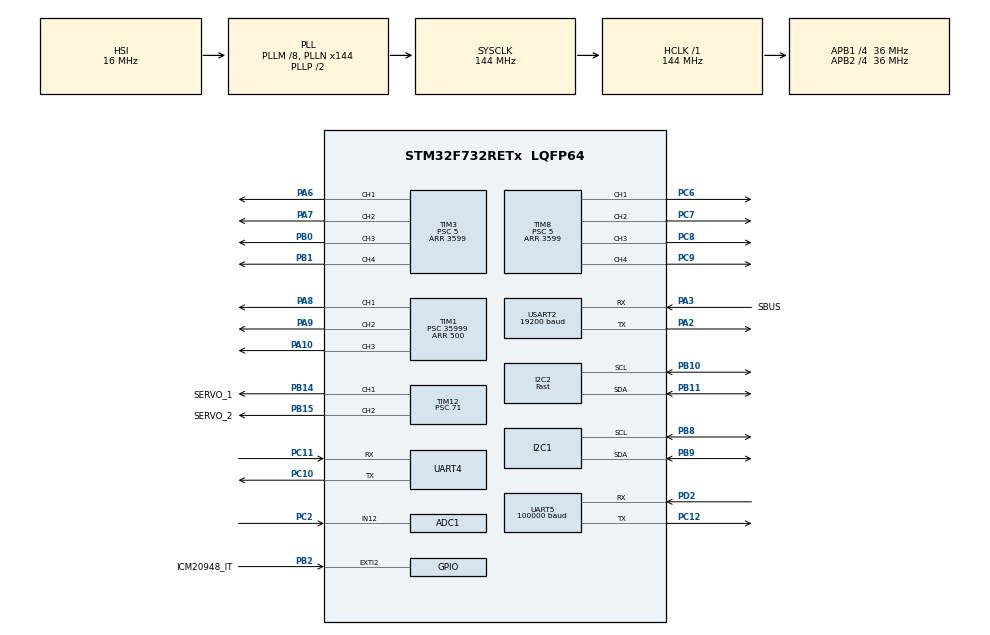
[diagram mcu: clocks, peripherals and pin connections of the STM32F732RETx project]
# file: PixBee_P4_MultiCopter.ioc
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ADC1.Channel-0\#ChannelRegularConversion=ADC_CHANNEL_12
ADC1.ContinuousConvMode=ENABLE
ADC1.DMAContinuousRequests=ENABLE
ADC1.NbrOfConversionFlag=1
ADC1.Rank-0\#ChannelRegularConversion=1
ADC1.Resolution=ADC_RESOLUTION_8B
ADC1.SamplingTime-0\#ChannelRegularConversion=ADC_SAMPLETIME_144CYCLES
ADC1.ScanConvMode=ADC_SCAN_ENABLE
ADC1.master=1
CORTEX_M7.ART_ACCELERATOR_ENABLE=1
CORTEX_M7.CPU_DCache=Enabled
CORTEX_M7.CPU_ICache=Enabled
CORTEX_M7.FlashInterface=AXI_Enabled
CORTEX_M7.MPU_Control=__NULL
CORTEX_M7.PREFETCH_ENABLE=1
CORTEX_M7.default_mode_Activation=1
Dma.ADC1.3.Direction=DMA_PERIPH_TO_MEMORY
Dma.ADC1.3.FIFOMode=DMA_FIFOMODE_DISABLE
Dma.ADC1.3.Instance=DMA2_Stream0
Dma.ADC1.3.MemDataAlignment=DMA_MDATAALIGN_HALFWORD
Dma.ADC1.3.MemInc=DMA_MINC_ENABLE
Dma.ADC1.3.Mode=DMA_CIRCULAR
Dma.ADC1.3.PeriphDataAlignment=DMA_PDATAALIGN_HALFWORD
Dma.ADC1.3.PeriphInc=DMA_PINC_DISABLE
Dma.ADC1.3.Priority=DMA_PRIORITY_LOW
Dma.Request0=UART5_RX
Dma.Request1=UART4_TX
Dma.Request2=USART2_TX
Dma.Request3=ADC1
Dma.UART4_TX.1.Direction=DMA_MEMORY_TO_PERIPH
Dma.UART4_TX.1.FIFOMode=DMA_FIFOMODE_DISABLE
Dma.UART4_TX.1.Instance=DMA1_Stream4
Dma.UART4_TX.1.MemDataAlignment=DMA_MDATAALIGN_BYTE
Dma.UART4_TX.1.MemInc=DMA_MINC_ENABLE
Dma.UART4_TX.1.Mode=DMA_NORMAL
Dma.UART4_TX.1.PeriphDataAlignment=DMA_PDATAALIGN_BYTE
Dma.UART4_TX.1.PeriphInc=DMA_PINC_DISABLE
Dma.UART4_TX.1.Priority=DMA_PRIORITY_LOW
Dma.UART5_RX.0.Direction=DMA_PERIPH_TO_MEMORY
Dma.UART5_RX.0.FIFOMode=DMA_FIFOMODE_DISABLE
Dma.UART5_RX.0.Instance=DMA1_Stream0
Dma.UART5_RX.0.MemDataAlignment=DMA_MDATAALIGN_BYTE
Dma.UART5_RX.0.MemInc=DMA_MINC_ENABLE
Dma.UART5_RX.0.Mode=DMA_NORMAL
Dma.UART5_RX.0.PeriphDataAlignment=DMA_PDATAALIGN_BYTE
Dma.UART5_RX.0.PeriphInc=DMA_PINC_DISABLE
Dma.UART5_RX.0.Priority=DMA_PRIORITY_LOW
Dma.USART2_TX.2.Direction=DMA_MEMORY_TO_PERIPH
Dma.USART2_TX.2.FIFOMode=DMA_FIFOMODE_DISABLE
Dma.USART2_TX.2.Instance=DMA1_Stream6
Dma.USART2_TX.2.MemDataAlignment=DMA_MDATAALIGN_BYTE
Dma.USART2_TX.2.MemInc=DMA_MINC_ENABLE
Dma.USART2_TX.2.Mode=DMA_NORMAL
Dma.USART2_TX.2.PeriphDataAlignment=DMA_PDATAALIGN_BYTE
Dma.USART2_TX.2.PeriphInc=DMA_PINC_DISABLE
Dma.USART2_TX.2.Priority=DMA_PRIORITY_LOW
I2C1.Timing=0x00808CD2
I2C2.I2C_Speed_Mode=I2C_Fast
I2C2.Timing=0x00301739
Mcu.Family=STM32F7
Mcu.Name=STM32F732RETx
Mcu.Package=LQFP64
NVIC.DMA1_Stream0_IRQn=true\:4\:0\:true\:false\:true\:false\:true\:true
NVIC.DMA1_Stream4_IRQn=true\:15\:0\:true\:false\:true\:false\:true\:true
NVIC.DMA1_Stream6_IRQn=true\:15\:0\:true\:false\:true\:false\:true\:true
NVIC.DMA2_Stream0_IRQn=true\:0\:0\:false\:false\:true\:false\:true\:true
NVIC.EXTI2_IRQn=true\:5\:0\:true\:false\:true\:true\:true\:true
NVIC.PriorityGroup=NVIC_PRIORITYGROUP_4
NVIC.TIM8_TRG_COM_TIM14_IRQn=true\:0\:0\:true\:false\:true\:true\:true\:true
NVIC.UART4_IRQn=true\:15\:0\:true\:false\:true\:true\:true\:true
NVIC.UART5_IRQn=true\:4\:0\:true\:false\:true\:true\:true\:true
NVIC.USART2_IRQn=true\:0\:0\:false\:false\:true\:true\:true\:true
PA0-WKUP.Signal=USART2_CTS
PA1.Signal=USART2_RTS
PA10.Signal=S_TIM1_CH3
PA13.Mode=Serial_Wire
PA13.Signal=SYS_JTMS-SWDIO
PA14.Mode=Serial_Wire
PA14.Signal=SYS_JTCK-SWCLK
PA2.Mode=Asynchronous
PA2.Signal=USART2_TX
PA3.GPIO_Label=SBUS
PA3.GPIO_PuPd=GPIO_PULLUP
PA3.Mode=Asynchronous
PA3.Signal=USART2_RX
PA6.Signal=S_TIM3_CH1
PA7.Signal=S_TIM3_CH2
PA8.Signal=S_TIM1_CH1
PA9.Signal=S_TIM1_CH2
PB0.Signal=S_TIM3_CH3
PB1.Signal=S_TIM3_CH4
PB10.Mode=I2C
PB10.Signal=I2C2_SCL
PB11.Mode=I2C
PB11.Signal=I2C2_SDA
PB14.GPIO_Label=SERVO_1
PB14.Signal=S_TIM12_CH1
PB15.GPIO_Label=SERVO_2
PB15.Signal=S_TIM12_CH2
PB2.GPIO_Label=ICM20948_IT
PB2.Signal=GPXTI2
PB3.Signal=SPI1_SCK
PB4.Signal=SPI1_MISO
PB5.Signal=SPI1_MOSI
PB8.Mode=I2C
PB8.Signal=I2C1_SCL
PB9.Mode=I2C
PB9.Signal=I2C1_SDA
PC10.Mode=Asynchronous
PC10.Signal=UART4_TX
PC11.Mode=Asynchronous
PC11.Signal=UART4_RX
PC12.Mode=Asynchronous
PC12.Signal=UART5_TX
PC2.Signal=ADCx_IN12
PC6.Signal=S_TIM8_CH1
PC7.Signal=S_TIM8_CH2
PC8.Signal=S_TIM8_CH3
PC9.Signal=S_TIM8_CH4
PD2.Mode=Asynchronous
PD2.Signal=UART5_RX
PH0-OSC_IN.Signal=RCC_OSC_IN
PH1-OSC_OUT.Signal=RCC_OSC_OUT
ProjectManager.HeapSize=0x200
ProjectManager.StackSize=0x400
ProjectManager.TargetToolchain=STM32CubeIDE
RCC.AHBFreq_Value=144000000
RCC.APB1CLKDivider=RCC_HCLK_DIV4
RCC.APB1Freq_Value=36000000
RCC.APB1TimFreq_Value=72000000
RCC.APB2CLKDivider=RCC_HCLK_DIV4
RCC.APB2Freq_Value=36000000
RCC.APB2TimFreq_Value=72000000
RCC.CortexFreq_Value=144000000
RCC.HCLKFreq_Value=144000000
RCC.HSE_VALUE=25000000
RCC.HSI_VALUE=16000000
RCC.LSE_VALUE=32768
RCC.PLL48CLockSelection=RCC_CLK48SOURCE_PLLSAIP
RCC.PLLM=8
RCC.PLLN=144
RCC.PLLQ=5
RCC.PLLSAIP=RCC_PLLSAIP_DIV4
RCC.SYSCLKFreq_VALUE=144000000
RCC.SYSCLKSource=RCC_SYSCLKSOURCE_PLLCLK
RCC.USBFreq_Value=96000000
RCC.VCOOutputFreq_Value=288000000
SH.ADCx_IN12.0=ADC1_IN12,IN12
SH.S_TIM12_CH1.0=TIM12_CH1,PWM Generation1 CH1
SH.S_TIM12_CH2.0=TIM12_CH2,PWM Generation2 CH2
SH.S_TIM1_CH1.0=TIM1_CH1,PWM Generation1 CH1
SH.S_TIM1_CH2.0=TIM1_CH2,PWM Generation2 CH2
SH.S_TIM1_CH3.0=TIM1_CH3,PWM Generation3 CH3
SH.S_TIM3_CH1.0=TIM3_CH1,PWM Generation1 CH1
SH.S_TIM3_CH2.0=TIM3_CH2,PWM Generation2 CH2
SH.S_TIM3_CH3.0=TIM3_CH3,PWM Generation3 CH3
SH.S_TIM3_CH4.0=TIM3_CH4,PWM Generation4 CH4
SH.S_TIM8_CH1.0=TIM8_CH1,PWM Generation1 CH1
SH.S_TIM8_CH2.0=TIM8_CH2,PWM Generation2 CH2
SH.S_TIM8_CH3.0=TIM8_CH3,PWM Generation3 CH3
SH.S_TIM8_CH4.0=TIM8_CH4,PWM Generation4 CH4
TIM1.Channel-PWM\ Generation1\ CH1=TIM_CHANNEL_1
TIM1.Channel-PWM\ Generation2\ CH2=TIM_CHANNEL_2
TIM1.Channel-PWM\ Generation3\ CH3=TIM_CHANNEL_3
TIM1.Period=500
TIM1.Prescaler=35999
TIM12.Channel-PWM\ Generation1\ CH1=TIM_CHANNEL_1
TIM12.Channel-PWM\ Generation2\ CH2=TIM_CHANNEL_2
TIM12.Period=2500
TIM12.Prescaler=71
TIM14.Channel=TIM_CHANNEL_1
TIM14.Period=999
TIM14.Prescaler=35999
TIM14.Pulse=499
TIM3.Channel-PWM\ Generation1\ CH1=TIM_CHANNEL_1
TIM3.Channel-PWM\ Generation2\ CH2=TIM_CHANNEL_2
TIM3.Channel-PWM\ Generation3\ CH3=TIM_CHANNEL_3
TIM3.Channel-PWM\ Generation4\ CH4=TIM_CHANNEL_4
TIM3.Period=3599
TIM3.Prescaler=5
TIM5.Prescaler=71
TIM8.Channel-PWM\ Generation1\ CH1=TIM_CHANNEL_1
TIM8.Channel-PWM\ Generation2\ CH2=TIM_CHANNEL_2
TIM8.Channel-PWM\ Generation3\ CH3=TIM_CHANNEL_3
TIM8.Channel-PWM\ Generation4\ CH4=TIM_CHANNEL_4
TIM8.Period=3599
TIM8.Prescaler=5
UART5.BaudRate=100000
UART5.Parity=PARITY_EVEN
UART5.RxPinLevelInvertParam=UART_ADVFEATURE_RXINV_ENABLE
UART5.StopBits=UART_STOPBITS_2
UART5.WordLength=WORDLENGTH_9B
USART2.BaudRate=19200
USART2.VirtualMode-Asynchronous=VM_ASYNC
VP_TIM14_VS_ClockSourceINT.Mode=Enable_Timer
VP_TIM14_VS_no_output1.Mode=PWM Generation1 No Output
VP_TIM3_VS_ClockSourceINT.Mode=Internal
VP_TIM5_VS_ClockSourceINT.Mode=Internal
board=custom

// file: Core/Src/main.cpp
/* USER CODE BEGIN Header */
/**
  ******************************************************************************
  * @file           : main.c
  * @brief          : Main program body
  ******************************************************************************
  * @attention
  *
  * Copyright (c) 2024 STMicroelectronics.
  * All rights reserved.
  *
  * This software is licensed under terms that can be found in the LICENSE file
  * in the root directory of this software component.
  * If no LICENSE file comes with this software, it is provided AS-IS.
  *
  ******************************************************************************
  */
/* USER CODE END Header */
#include "main.h"
#include "adc.h"
#include "dma.h"
#include "i2c.h"
#include "tim.h"
#include "usart.h"
#include "gpio.h"

/* USER CODE BEGIN Includes */
#include "wrapper.hpp"
/* USER CODE END Includes */

void SystemClock_Config(void);

int main(void)
{

  /* Enable the CPU Cache */

  /* Enable I-Cache---------------------------------------------------------*/
  SCB_EnableICache();

  /* Enable D-Cache---------------------------------------------------------*/
  SCB_EnableDCache();

  /* MCU Configuration--------------------------------------------------------*/

  /* Reset of all peripherals, Initializes the Flash interface and the Systick. */
  HAL_Init();

  /* Configure the system clock */
  SystemClock_Config();

  /* USER CODE BEGIN SysInit */
  SET_MASK_ICM20948_INTERRUPT();
  /* USER CODE END SysInit */

  /* Initialize all configured peripherals */
  MX_GPIO_Init();
  MX_DMA_Init();
  MX_TIM5_Init();
  MX_TIM14_Init();
  MX_TIM3_Init();
  MX_UART5_Init();
  MX_I2C1_Init();
  MX_UART4_Init();
  MX_I2C2_Init();
  MX_TIM8_Init();
  MX_TIM12_Init();
  MX_TIM1_Init();
  MX_USART2_UART_Init();
  MX_ADC1_Init();
  /* USER CODE BEGIN 2 */
init();
  /* USER CODE END 2 */

  /* Infinite loop */
  /* USER CODE BEGIN WHILE */
  while (1)
  {
	  loop();
    /* USER CODE END WHILE */

  }
}

void SystemClock_Config(void)
{
  RCC_OscInitTypeDef RCC_OscInitStruct = {0};
  RCC_ClkInitTypeDef RCC_ClkInitStruct = {0};

  /** Configure the main internal regulator output voltage
  */
  __HAL_RCC_PWR_CLK_ENABLE();
  __HAL_PWR_VOLTAGESCALING_CONFIG(PWR_REGULATOR_VOLTAGE_SCALE3);

  /** Initializes the RCC Oscillators according to the specified parameters
  * in the RCC_OscInitTypeDef structure.
  */
  RCC_OscInitStruct.OscillatorType = RCC_OSCILLATORTYPE_HSI;
  RCC_OscInitStruct.HSIState = RCC_HSI_ON;
  RCC_OscInitStruct.HSICalibrationValue = RCC_HSICALIBRATION_DEFAULT;
  RCC_OscInitStruct.PLL.PLLState = RCC_PLL_ON;
  RCC_OscInitStruct.PLL.PLLSource = RCC_PLLSOURCE_HSI;
  RCC_OscInitStruct.PLL.PLLM = 8;
  RCC_OscInitStruct.PLL.PLLN = 144;
  RCC_OscInitStruct.PLL.PLLP = RCC_PLLP_DIV2;
  RCC_OscInitStruct.PLL.PLLQ = 5;
  if (HAL_RCC_OscConfig(&RCC_OscInitStruct) != HAL_OK)
  {
    Error_Handler();
  }

  /** Initializes the CPU, AHB and APB buses clocks
  */
  RCC_ClkInitStruct.ClockType = RCC_CLOCKTYPE_HCLK|RCC_CLOCKTYPE_SYSCLK
                              |RCC_CLOCKTYPE_PCLK1|RCC_CLOCKTYPE_PCLK2;
  RCC_ClkInitStruct.SYSCLKSource = RCC_SYSCLKSOURCE_PLLCLK;
  RCC_ClkInitStruct.AHBCLKDivider = RCC_SYSCLK_DIV1;
  RCC_ClkInitStruct.APB1CLKDivider = RCC_HCLK_DIV4;
  RCC_ClkInitStruct.APB2CLKDivider = RCC_HCLK_DIV4;

  if (HAL_RCC_ClockConfig(&RCC_ClkInitStruct, FLASH_LATENCY_4) != HAL_OK)
  {
    Error_Handler();
  }
}

void Error_Handler(void)
{
  __disable_irq();
  while (1)
  {
  }
}
